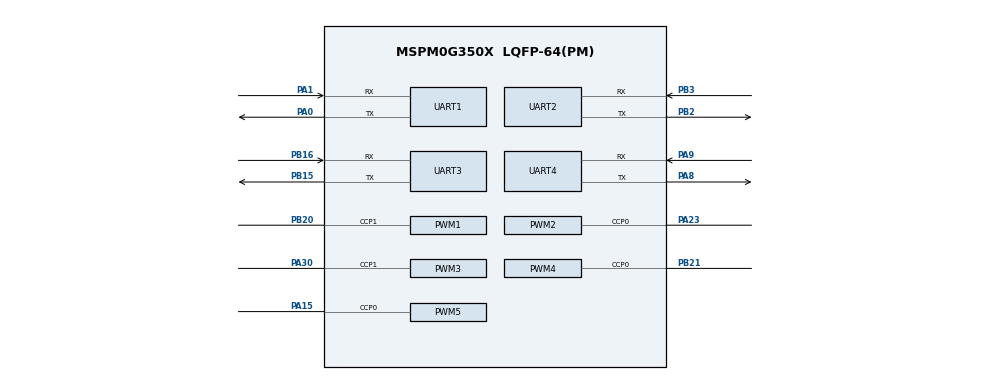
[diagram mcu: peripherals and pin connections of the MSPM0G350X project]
/**
 * @cliArgs --device "MSPM0G350X" --package "LQFP-64(PM)" --part "Default" --product "mspm0_sdk@2.01.00.03"
 * @versions {"tool":"1.20.0+3587"}
 */

/**
 * Import the modules used in this configuration.
 */
const GPIO   = scripting.addModule("/ti/driverlib/GPIO", {}, false);
const GPIO1  = GPIO.addInstance();
const GPIO2  = GPIO.addInstance();
const GPIO3  = GPIO.addInstance();
const GPIO4  = GPIO.addInstance();
const GPIO5  = GPIO.addInstance();
const GPIO6  = GPIO.addInstance();
const GPIO7  = GPIO.addInstance();
const I2C    = scripting.addModule("/ti/driverlib/I2C", {}, false);
const I2C1   = I2C.addInstance();
const PWM    = scripting.addModule("/ti/driverlib/PWM", {}, false);
const PWM1   = PWM.addInstance();
const PWM2   = PWM.addInstance();
const PWM3   = PWM.addInstance();
const PWM4   = PWM.addInstance();
const PWM5   = PWM.addInstance();
const SYSCTL = scripting.addModule("/ti/driverlib/SYSCTL");
const TIMER  = scripting.addModule("/ti/driverlib/TIMER", {}, false);
const TIMER1 = TIMER.addInstance();
const TIMER2 = TIMER.addInstance();
const UART   = scripting.addModule("/ti/driverlib/UART", {}, false);
const UART1  = UART.addInstance();
const UART2  = UART.addInstance();
const UART3  = UART.addInstance();
const UART4  = UART.addInstance();

/**
 * Write custom configuration values to the imported modules.
 */
GPIO1.$name                          = "GPIO_SPI";
GPIO1.associatedPins.create(6);
GPIO1.associatedPins[0].$name        = "SCL";
GPIO1.associatedPins[0].initialValue = "SET";
GPIO1.associatedPins[0].assignedPort = "PORTB";
GPIO1.associatedPins[0].assignedPin  = "9";
GPIO1.associatedPins[1].$name        = "SDA";
GPIO1.associatedPins[1].initialValue = "SET";
GPIO1.associatedPins[1].assignedPort = "PORTB";
GPIO1.associatedPins[1].assignedPin  = "8";
GPIO1.associatedPins[2].$name        = "RSE";
GPIO1.associatedPins[2].initialValue = "SET";
GPIO1.associatedPins[2].assignedPort = "PORTB";
GPIO1.associatedPins[2].assignedPin  = "10";
GPIO1.associatedPins[3].$name        = "DC";
GPIO1.associatedPins[3].initialValue = "SET";
GPIO1.associatedPins[3].assignedPort = "PORTB";
GPIO1.associatedPins[3].assignedPin  = "11";
GPIO1.associatedPins[4].$name        = "CS";
GPIO1.associatedPins[4].initialValue = "SET";
GPIO1.associatedPins[4].assignedPort = "PORTB";
GPIO1.associatedPins[4].assignedPin  = "14";
GPIO1.associatedPins[5].$name        = "BLK";
GPIO1.associatedPins[5].initialValue = "SET";
GPIO1.associatedPins[5].assignedPort = "PORTB";
GPIO1.associatedPins[5].assignedPin  = "26";

const Board = scripting.addModule("/ti/driverlib/Board", {}, false);

GPIO2.$name                              = "GPIO_Re";
GPIO2.associatedPins.create(3);
GPIO2.associatedPins[0].$name            = "PIN_14";
GPIO2.associatedPins[0].direction        = "INPUT";
GPIO2.associatedPins[0].assignedPort     = "PORTA";
GPIO2.associatedPins[0].assignedPin      = "14";
GPIO2.associatedPins[0].internalResistor = "PULL_UP";
GPIO2.associatedPins[0].interruptEn      = true;
GPIO2.associatedPins[0].polarity         = "FALL";
GPIO2.associatedPins[1].$name            = "PIN_16";
GPIO2.associatedPins[1].direction        = "INPUT";
GPIO2.associatedPins[1].internalResistor = "PULL_UP";
GPIO2.associatedPins[1].interruptEn      = true;
GPIO2.associatedPins[1].polarity         = "FALL";
GPIO2.associatedPins[1].assignedPort     = "PORTA";
GPIO2.associatedPins[1].assignedPin      = "16";
GPIO2.associatedPins[2].$name            = "PIN_25";
GPIO2.associatedPins[2].direction        = "INPUT";
GPIO2.associatedPins[2].internalResistor = "PULL_UP";
GPIO2.associatedPins[2].inputFilter      = "8_CYCLES";
GPIO2.associatedPins[2].interruptEn      = true;
GPIO2.associatedPins[2].polarity         = "FALL";
GPIO2.associatedPins[2].assignedPort     = "PORTA";
GPIO2.associatedPins[2].assignedPin      = "25";

GPIO3.$name                               = "Switch";
GPIO3.associatedPins.create(3);
GPIO3.associatedPins[0].$name             = "K1";
GPIO3.associatedPins[0].direction         = "INPUT";
GPIO3.associatedPins[0].assignedPort      = "PORTB";
GPIO3.associatedPins[0].assignedPin       = "1";
GPIO3.associatedPins[0].inputFilter       = "8_CYCLES";
GPIO3.associatedPins[0].interruptEn       = true;
GPIO3.associatedPins[0].interruptPriority = "1";
GPIO3.associatedPins[0].polarity          = "FALL";
GPIO3.associatedPins[1].$name             = "K2";
GPIO3.associatedPins[1].direction         = "INPUT";
GPIO3.associatedPins[1].inputFilter       = "8_CYCLES";
GPIO3.associatedPins[1].assignedPort      = "PORTB";
GPIO3.associatedPins[1].assignedPin       = "24";
GPIO3.associatedPins[1].interruptEn       = true;
GPIO3.associatedPins[1].polarity          = "FALL";
GPIO3.associatedPins[2].$name             = "K3";
GPIO3.associatedPins[2].direction         = "INPUT";
GPIO3.associatedPins[2].inputFilter       = "8_CYCLES";
GPIO3.associatedPins[2].assignedPort      = "PORTB";
GPIO3.associatedPins[2].assignedPin       = "25";
GPIO3.associatedPins[2].interruptEn       = true;
GPIO3.associatedPins[2].polarity          = "FALL";

GPIO4.$name                          = "Stepping_GPIO";
GPIO4.associatedPins.create(8);
GPIO4.associatedPins[0].$name        = "DIR_1";
GPIO4.associatedPins[0].assignedPort = "PORTB";
GPIO4.associatedPins[0].assignedPin  = "4";
GPIO4.associatedPins[1].$name        = "MS2_1";
GPIO4.associatedPins[1].assignedPort = "PORTB";
GPIO4.associatedPins[1].assignedPin  = "12";
GPIO4.associatedPins[2].$name        = "MS1_1";
GPIO4.associatedPins[2].assignedPort = "PORTB";
GPIO4.associatedPins[2].assignedPin  = "13";
GPIO4.associatedPins[3].$name        = "EN_1";
GPIO4.associatedPins[3].assignedPort = "PORTB";
GPIO4.associatedPins[3].assignedPin  = "7";
GPIO4.associatedPins[4].$name        = "MS2_2";
GPIO4.associatedPins[4].assignedPin  = "5";
GPIO4.associatedPins[4].assignedPort = "PORTB";
GPIO4.associatedPins[5].$name        = "MS1_2";
GPIO4.associatedPins[5].assignedPort = "PORTB";
GPIO4.associatedPins[5].assignedPin  = "22";
GPIO4.associatedPins[6].assignedPort = "PORTA";
GPIO4.associatedPins[6].assignedPin  = "12";
GPIO4.associatedPins[6].$name        = "DIR_2";
GPIO4.associatedPins[7].$name        = "EN_2";
GPIO4.associatedPins[7].assignedPort = "PORTB";
GPIO4.associatedPins[7].assignedPin  = "0";

GPIO5.$name                              = "LED";
GPIO5.associatedPins.create(3);
GPIO5.associatedPins[0].$name            = "Red";
GPIO5.associatedPins[0].internalResistor = "PULL_UP";
GPIO5.associatedPins[0].assignedPort     = "PORTB";
GPIO5.associatedPins[0].assignedPin      = "6";
GPIO5.associatedPins[1].$name            = "Blue";
GPIO5.associatedPins[1].assignedPort     = "PORTB";
GPIO5.associatedPins[1].assignedPin      = "27";
GPIO5.associatedPins[1].internalResistor = "PULL_UP";
GPIO5.associatedPins[2].$name            = "Green";
GPIO5.associatedPins[2].assignedPort     = "PORTB";
GPIO5.associatedPins[2].assignedPin      = "23";
GPIO5.associatedPins[2].internalResistor = "PULL_UP";

GPIO6.$name                          = "Stepping_Gimbal_GPIO";
GPIO6.associatedPins.create(4);
GPIO6.associatedPins[0].assignedPort = "PORTB";
GPIO6.associatedPins[0].$name        = "Gimbal_DIR_Up";
GPIO6.associatedPins[0].assignedPin  = "18";
GPIO6.associatedPins[1].assignedPort = "PORTB";
GPIO6.associatedPins[1].$name        = "Gimbal_EN_Up";
GPIO6.associatedPins[1].assignedPin  = "19";
GPIO6.associatedPins[2].$name        = "Gimbal_EN_Down";
GPIO6.associatedPins[2].assignedPort = "PORTA";
GPIO6.associatedPins[2].assignedPin  = "24";
GPIO6.associatedPins[3].assignedPort = "PORTA";
GPIO6.associatedPins[3].$name        = "Gimbal_DIR_Down";
GPIO6.associatedPins[3].assignedPin  = "13";

GPIO7.$name                          = "Electromagnets_IO";
GPIO7.associatedPins[0].assignedPort = "PORTB";
GPIO7.associatedPins[0].$name        = "PB17";

I2C1.$name                           = "I2C_0";
I2C1.basicEnableController           = true;
I2C1.basicControllerStandardBusSpeed = "Fast";
I2C1.sdaPinConfig.$name              = "ti_driverlib_gpio_GPIOPinGeneric4";
I2C1.sdaPinConfig.enableConfig       = true;
I2C1.sdaPinConfig.internalResistor   = "PULL_UP";
I2C1.sclPinConfig.$name              = "ti_driverlib_gpio_GPIOPinGeneric5";
I2C1.sclPinConfig.enableConfig       = true;
I2C1.sclPinConfig.internalResistor   = "PULL_UP";

PWM1.timerCount                         = 1;
PWM1.pwmMode                            = "EDGE_ALIGN_UP";
PWM1.interrupts                         = ["ZERO_EVENT"];
PWM1.ccIndex                            = [1];
PWM1.clockPrescale                      = 32;
PWM1.interruptPriority                  = "1";
PWM1.$name                              = "Stepping_STEP_L";
PWM1.peripheral.$assign                 = "TIMA0";
PWM1.peripheral.ccp1Pin.$assign         = "PB20";
PWM1.ccp1PinConfig.direction            = scripting.forceWrite("OUTPUT");
PWM1.ccp1PinConfig.hideOutputInversion  = scripting.forceWrite(false);
PWM1.ccp1PinConfig.onlyInternalResistor = scripting.forceWrite(false);
PWM1.ccp1PinConfig.passedPeripheralType = scripting.forceWrite("Digital");
PWM1.ccp1PinConfig.$name                = "ti_driverlib_gpio_GPIOPinGeneric1";
PWM1.PWM_CHANNEL_1.$name                = "ti_driverlib_pwm_PWMTimerCC0";

PWM2.ccIndex                            = [0];
PWM2.clockPrescale                      = 32;
PWM2.timerCount                         = 1;
PWM2.pwmMode                            = "EDGE_ALIGN_UP";
PWM2.interrupts                         = ["ZERO_EVENT"];
PWM2.$name                              = "Stepping_STEP_R";
PWM2.peripheral.$assign                 = "TIMG0";
PWM2.peripheral.ccp0Pin.$assign         = "PA23";
PWM2.PWM_CHANNEL_0.$name                = "ti_driverlib_pwm_PWMTimerCC1";
PWM2.ccp0PinConfig.direction            = scripting.forceWrite("OUTPUT");
PWM2.ccp0PinConfig.hideOutputInversion  = scripting.forceWrite(false);
PWM2.ccp0PinConfig.onlyInternalResistor = scripting.forceWrite(false);
PWM2.ccp0PinConfig.passedPeripheralType = scripting.forceWrite("Digital");
PWM2.ccp0PinConfig.$name                = "ti_driverlib_gpio_GPIOPinGeneric6";

PWM3.timerCount                         = 1;
PWM3.pwmMode                            = "EDGE_ALIGN_UP";
PWM3.interrupts                         = ["ZERO_EVENT"];
PWM3.clockPrescale                      = 32;
PWM3.$name                              = "Stepping_Gimbal_STEP_Up";
PWM3.interruptPriority                  = "0";
PWM3.ccIndex                            = [1];
PWM3.peripheral.$assign                 = "TIMG6";
PWM3.peripheral.ccp1Pin.$assign         = "PA30";
PWM3.ccp1PinConfig.direction            = scripting.forceWrite("OUTPUT");
PWM3.ccp1PinConfig.hideOutputInversion  = scripting.forceWrite(false);
PWM3.ccp1PinConfig.onlyInternalResistor = scripting.forceWrite(false);
PWM3.ccp1PinConfig.passedPeripheralType = scripting.forceWrite("Digital");
PWM3.ccp1PinConfig.$name                = "ti_driverlib_gpio_GPIOPinGeneric15";
PWM3.PWM_CHANNEL_1.$name                = "ti_driverlib_pwm_PWMTimerCC2";

PWM4.timerCount                         = 1;
PWM4.pwmMode                            = "EDGE_ALIGN_UP";
PWM4.interrupts                         = ["ZERO_EVENT"];
PWM4.clockPrescale                      = 32;
PWM4.$name                              = "Stepping_Gimbal_STEP_Down";
PWM4.interruptPriority                  = "0";
PWM4.ccIndex                            = [0];
PWM4.peripheral.$assign                 = "TIMG8";
PWM4.peripheral.ccp0Pin.$assign         = "PB21";
PWM4.PWM_CHANNEL_0.$name                = "ti_driverlib_pwm_PWMTimerCC4";
PWM4.ccp0PinConfig.direction            = scripting.forceWrite("OUTPUT");
PWM4.ccp0PinConfig.hideOutputInversion  = scripting.forceWrite(false);
PWM4.ccp0PinConfig.onlyInternalResistor = scripting.forceWrite(false);
PWM4.ccp0PinConfig.passedPeripheralType = scripting.forceWrite("Digital");
PWM4.ccp0PinConfig.$name                = "ti_driverlib_gpio_GPIOPinGeneric14";

PWM5.$name                              = "PWM_Servos";
PWM5.ccIndex                            = [0];
PWM5.clockPrescale                      = 100;
PWM5.timerCount                         = 6400;
PWM5.pwmMode                            = "EDGE_ALIGN_UP";
PWM5.peripheral.$assign                 = "TIMA1";
PWM5.peripheral.ccp0Pin.$assign         = "PA15";
PWM5.PWM_CHANNEL_0.$name                = "ti_driverlib_pwm_PWMTimerCC3";
PWM5.ccp0PinConfig.direction            = scripting.forceWrite("OUTPUT");
PWM5.ccp0PinConfig.hideOutputInversion  = scripting.forceWrite(false);
PWM5.ccp0PinConfig.onlyInternalResistor = scripting.forceWrite(false);
PWM5.ccp0PinConfig.passedPeripheralType = scripting.forceWrite("Digital");
PWM5.ccp0PinConfig.$name                = "ti_driverlib_gpio_GPIOPinGeneric11";

SYSCTL.forceDefaultClkConfig = true;

TIMER1.timerClkDiv        = 8;
TIMER1.timerMode          = "PERIODIC";
TIMER1.interrupts         = ["ZERO"];
TIMER1.interruptPriority  = "0";
TIMER1.$name              = "Trace_Timer";
TIMER1.timerPeriod        = "5ms";
TIMER1.peripheral.$assign = "TIMG7";

TIMER2.$name       = "TIMER_0";
TIMER2.timerPeriod = "10ms";
TIMER2.timerClkDiv = 8;
TIMER2.timerMode   = "PERIODIC";
TIMER2.interrupts  = ["ZERO"];

UART1.$name                    = "UART_0";
UART1.enabledInterrupts        = ["RX"];
UART1.targetBaudRate           = 115200;
UART1.interruptPriority        = "1";
UART1.peripheral.$assign       = "UART0";
UART1.peripheral.rxPin.$assign = "PA1";
UART1.peripheral.txPin.$assign = "PA0";
UART1.txPinConfig.$name        = "ti_driverlib_gpio_GPIOPinGeneric0";
UART1.rxPinConfig.$name        = "ti_driverlib_gpio_GPIOPinGeneric2";

UART2.$name                            = "UART_3_R";
UART2.targetBaudRate                   = 115200;
UART2.enabledInterrupts                = ["RX"];
UART2.interruptPriority                = "0";
UART2.peripheral.$assign               = "UART3";
UART2.peripheral.rxPin.$assign         = "PB3";
UART2.peripheral.txPin.$assign         = "PB2";
UART2.txPinConfig.direction            = scripting.forceWrite("OUTPUT");
UART2.txPinConfig.hideOutputInversion  = scripting.forceWrite(false);
UART2.txPinConfig.onlyInternalResistor = scripting.forceWrite(false);
UART2.txPinConfig.passedPeripheralType = scripting.forceWrite("Digital");
UART2.txPinConfig.$name                = "ti_driverlib_gpio_GPIOPinGeneric3";
UART2.rxPinConfig.hideOutputInversion  = scripting.forceWrite(false);
UART2.rxPinConfig.onlyInternalResistor = scripting.forceWrite(false);
UART2.rxPinConfig.passedPeripheralType = scripting.forceWrite("Digital");
UART2.rxPinConfig.$name                = "ti_driverlib_gpio_GPIOPinGeneric7";

UART3.$name                            = "UART_2_L";
UART3.targetBaudRate                   = 115200;
UART3.enabledInterrupts                = ["RX"];
UART3.interruptPriority                = "0";
UART3.peripheral.$assign               = "UART2";
UART3.peripheral.rxPin.$assign         = "PB16";
UART3.peripheral.txPin.$assign         = "PB15";
UART3.txPinConfig.direction            = scripting.forceWrite("OUTPUT");
UART3.txPinConfig.hideOutputInversion  = scripting.forceWrite(false);
UART3.txPinConfig.onlyInternalResistor = scripting.forceWrite(false);
UART3.txPinConfig.passedPeripheralType = scripting.forceWrite("Digital");
UART3.txPinConfig.$name                = "ti_driverlib_gpio_GPIOPinGeneric8";
UART3.rxPinConfig.hideOutputInversion  = scripting.forceWrite(false);
UART3.rxPinConfig.onlyInternalResistor = scripting.forceWrite(false);
UART3.rxPinConfig.passedPeripheralType = scripting.forceWrite("Digital");
UART3.rxPinConfig.$name                = "ti_driverlib_gpio_GPIOPinGeneric9";

UART4.$name                            = "UART_1";
UART4.enabledInterrupts                = ["RX"];
UART4.interruptPriority                = "1";
UART4.targetBaudRate                   = 115200;
UART4.peripheral.$assign               = "UART1";
UART4.peripheral.rxPin.$assign         = "PA9";
UART4.peripheral.txPin.$assign         = "PA8";
UART4.txPinConfig.direction            = scripting.forceWrite("OUTPUT");
UART4.txPinConfig.hideOutputInversion  = scripting.forceWrite(false);
UART4.txPinConfig.onlyInternalResistor = scripting.forceWrite(false);
UART4.txPinConfig.passedPeripheralType = scripting.forceWrite("Digital");
UART4.txPinConfig.$name                = "ti_driverlib_gpio_GPIOPinGeneric12";
UART4.rxPinConfig.hideOutputInversion  = scripting.forceWrite(false);
UART4.rxPinConfig.onlyInternalResistor = scripting.forceWrite(false);
UART4.rxPinConfig.passedPeripheralType = scripting.forceWrite("Digital");
UART4.rxPinConfig.$name                = "ti_driverlib_gpio_GPIOPinGeneric13";

/**
 * Pinmux solution for unlocked pins/peripherals. This ensures that minor changes to the automatic solver in a future
 * version of the tool will not impact the pinmux you originally saw.  These lines can be completely deleted in order to
 * re-solve from scratch.
 */
GPIO1.associatedPins[0].pin.$suggestSolution = "PB9";
GPIO1.associatedPins[1].pin.$suggestSolution = "PB8";
GPIO1.associatedPins[2].pin.$suggestSolution = "PB10";
GPIO1.associatedPins[3].pin.$suggestSolution = "PB11";
GPIO1.associatedPins[4].pin.$suggestSolution = "PB14";
GPIO1.associatedPins[5].pin.$suggestSolution = "PB26";
Board.peripheral.$suggestSolution            = "DEBUGSS";
Board.peripheral.swclkPin.$suggestSolution   = "PA20";
Board.peripheral.swdioPin.$suggestSolution   = "PA19";
GPIO2.associatedPins[0].pin.$suggestSolution = "PA14";
GPIO2.associatedPins[1].pin.$suggestSolution = "PA16";
GPIO2.associatedPins[2].pin.$suggestSolution = "PA25";
GPIO3.associatedPins[0].pin.$suggestSolution = "PB1";
GPIO3.associatedPins[1].pin.$suggestSolution = "PB24";
GPIO3.associatedPins[2].pin.$suggestSolution = "PB25";
GPIO4.associatedPins[0].pin.$suggestSolution = "PB4";
GPIO4.associatedPins[1].pin.$suggestSolution = "PB12";
GPIO4.associatedPins[2].pin.$suggestSolution = "PB13";
GPIO4.associatedPins[3].pin.$suggestSolution = "PB7";
GPIO4.associatedPins[4].pin.$suggestSolution = "PB5";
GPIO4.associatedPins[5].pin.$suggestSolution = "PB22";
GPIO4.associatedPins[6].pin.$suggestSolution = "PA12";
GPIO4.associatedPins[7].pin.$suggestSolution = "PB0";
GPIO5.associatedPins[0].pin.$suggestSolution = "PB6";
GPIO5.associatedPins[1].pin.$suggestSolution = "PB27";
GPIO5.associatedPins[2].pin.$suggestSolution = "PB23";
GPIO6.associatedPins[0].pin.$suggestSolution = "PB18";
GPIO6.associatedPins[1].pin.$suggestSolution = "PB19";
GPIO6.associatedPins[2].pin.$suggestSolution = "PA24";
GPIO6.associatedPins[3].pin.$suggestSolution = "PA13";
GPIO7.associatedPins[0].pin.$suggestSolution = "PB17";
I2C1.peripheral.$suggestSolution             = "I2C0";
I2C1.peripheral.sdaPin.$suggestSolution      = "PA10";
I2C1.peripheral.sclPin.$suggestSolution      = "PA11";
SYSCTL.peripheral.$suggestSolution           = "SYSCTL";
TIMER2.peripheral.$suggestSolution           = "TIMG12";
